# PIC32CM5164JH01100 device description
Architecture: CORTEX-M0PLUS; Family: PIC32CM; Series: PIC32CMJH01
Registers are 32-bit, read-write, reset 0x0 unless marked. A register's access mark holds for its fields unless they carry their own. Offsets are from the block's base; [hi:lo] are bit positions; {n}, {i} and the like mark numbered series.

## ICM_DESCRIPTOR — Integrity Check Monitor
0x00 RADDR reset not defined — Region Start Address
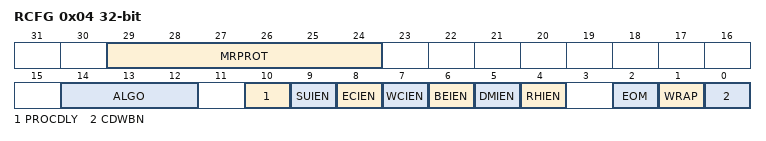
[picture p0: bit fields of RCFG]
0x04 RCFG — Region Configuration
  [29:24] MRPROT — Memory Region AHB Protection
  [14:12] ALGO — SHA Algorithm
  [10] PROCDLY — SHA Processing Delay
    0=SHORT; 1=LONG
  [9] SUIEN — Region Status Updated Interrupt Enable
    0=EN; 1=DIS
  [8] ECIEN — Region End bit Condition detected Interrupt Enable
    0=EN; 1=DIS
  [7] WCIEN — Region Wrap Condition Detected Interrupt Enable
    0=EN; 1=DIS
  [6] BEIEN — Region Bus Error Interrupt Enable
    0=EN; 1=DIS
  [5] DMIEN — Region Digest Mismatch Interrupt Enable
    0=EN; 1=DIS
  [4] RHIEN — Region Hash Interrupt Enable
    0=EN; 1=DIS
  [2] EOM — End of Monitoring
    0=NO; 1=YES
  [1] WRAP — Region Wrap
    0=NO; 1=YES
  [0] CDWBN — Compare Digest Write Back
    0=WRBA; 1=COMP
0x08 RCTRL reset not defined — Region Control
  [15:0] TRSIZE — Transfer Size
0x0C RNEXT reset not defined — Region Next Address

## SMBIST — SRAM MBIST Interface
Instances: SMBIST 0x42006c00
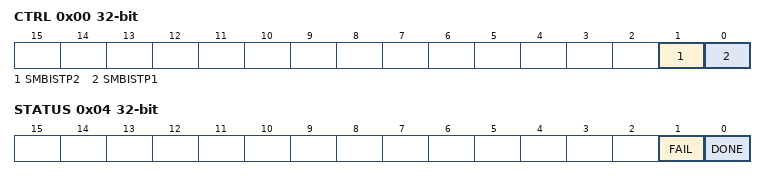
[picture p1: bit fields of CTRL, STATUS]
0x00 CTRL — Control
  [1] SMBISTP2 — SRAM MBIST Partition 2 test start
  [0] SMBISTP1 — SRAM MBIST Partition 1 test start
0x04 STATUS
  [1] FAIL, [0] DONE

## MCLK — Main Clock
Instances: MCLK 0x40000800
0x01 INTENCLR 8-bit (atomic clear) — Interrupt Enable Clear
  [0] CKRDY — Clock Ready Interrupt Enable
0x02 INTENSET 8-bit (atomic set) — Interrupt Enable Set
  [0] CKRDY — Clock Ready Interrupt Enable
0x03 INTFLAG 8-bit reset 0x1 (atomic clear) — Interrupt Flag Status and Clear
  [0] CKRDY — Clock Ready
0x04 CPUDIV 8-bit reset 0x1 — CPU Clock Division
  [7:0] CPUDIV — CPU Clock Division Factor
    1=DIV1 (Divide by 1); 2=DIV2 (Divide by 2); 4=DIV4 (Divide by 4); 8=DIV8 (Divide by 8); 16=DIV16 (Divide by 16); 32=DIV32 (Divide by 32); 64=DIV64 (Divide by 64); 128=DIV128 (Divide by 128)
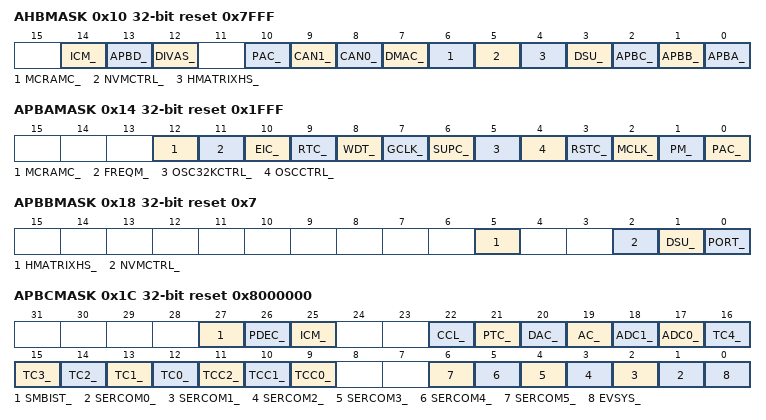
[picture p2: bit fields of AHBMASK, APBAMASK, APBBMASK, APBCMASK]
0x10 AHBMASK reset 0x7FFF
  [14] ICM_ — ICM AHB Clock Mask
  [13] APBD_ — APBD AHB Clock Mask
  [12] DIVAS_ — DIVAS AHB Clock Mask
  [10] PAC_ — PAC AHB Clock Mask
  [9] CAN1_ — CAN1 AHB Clock Mask
  [8] CAN0_ — CAN0 AHB Clock Mask
  [7] DMAC_ — DMAC AHB Clock Mask
  [6] MCRAMC_ — MCRAMC AHB Clock Mask
  [5] NVMCTRL_ — NVMCTRL AHB Clock Mask
  [4] HMATRIXHS_ — HMATRIXHS AHB Clock Mask
  [3] DSU_ — DSU AHB Clock Mask
  [2] APBC_ — APBC AHB Clock Mask
  [1] APBB_ — APBB AHB Clock Mask
  [0] APBA_ — APBA AHB Clock Mask
0x14 APBAMASK reset 0x1FFF
  [12] MCRAMC_ — MCRAMC APB Clock Enable
  [11] FREQM_ — FREQM APB Clock Enable
  [10] EIC_ — EIC APB Clock Enable
  [9] RTC_ — RTC APB Clock Enable
  [8] WDT_ — WDT APB Clock Enable
  [7] GCLK_ — GCLK APB Clock Enable
  [6] SUPC_ — SUPC APB Clock Enable
  [5] OSC32KCTRL_ — OSC32KCTRL APB Clock Enable
  [4] OSCCTRL_ — OSCCTRL APB Clock Enable
  [3] RSTC_ — RSTC APB Clock Enable
  [2] MCLK_ — MCLK APB Clock Enable
  [1] PM_ — PM APB Clock Enable
  [0] PAC_ — PAC APB Clock Enable
0x18 APBBMASK reset 0x7
  [5] HMATRIXHS_ — HMATRIXHS APB Clock Enable
  [2] NVMCTRL_ — NVMCTRL APB Clock Enable
  [1] DSU_ — DSU APB Clock Enable
  [0] PORT_ — PORT APB Clock Enable
0x1C APBCMASK reset 0x8000000
  [27] SMBIST_ — SMBIST APB Clock Enable
  [26] PDEC_ — PDEC APB Clock Enable
  [25] ICM_ — ICM APB Clock Enable
  [22] CCL_ — CCL APB Clock Enable
  [21] PTC_ — PTC APB Clock Enable
  [20] DAC_ — DAC APB Clock Enable
  [19] AC_ — AC APB Clock Enable
  [18] ADC1_ — ADC1 APB Clock Enable
  [17] ADC0_ — ADC0 APB Clock Enable
  [n+12] TC{n}_ (n=0..4) — TC{n} APB Clock Enable
  [11] TCC2_ — TCC2 APB Clock Enable
  [10] TCC1_ — TCC1 APB Clock Enable
  [9] TCC0_ — TCC0 APB Clock Enable
  [n+1] SERCOM{n}_ (n=0..5) — SERCOM{n} APB Clock Enable
  [0] EVSYS_ — EVSYS APB Clock Enable
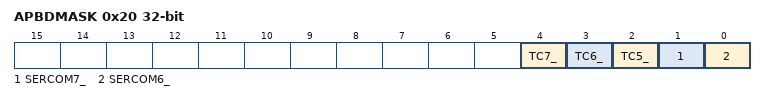
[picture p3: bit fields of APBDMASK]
0x20 APBDMASK
  [4] TC7_ — TC7 APB Clock Enable
  [3] TC6_ — TC6 APB Clock Enable
  [2] TC5_ — TC5 APB Clock Enable
  [1] SERCOM7_ — SERCOM7 APB Clock Enable
  [0] SERCOM6_ — SERCOM6 APB Clock Enable
